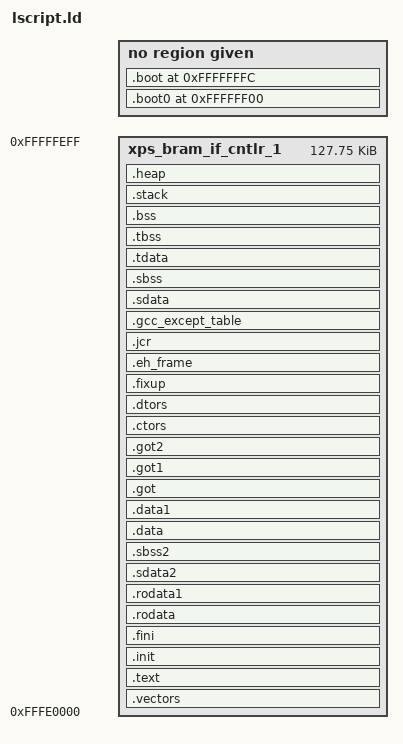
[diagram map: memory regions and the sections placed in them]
/*******************************************************************/
/*                                                                 */
/* This file is automatically generated by linker script generator.*/
/*                                                                 */
/* Version: Xilinx EDK 13.4 EDK_O.87xd                                */
/*                                                                 */
/* Copyright (c) 2010 Xilinx, Inc.  All rights reserved.           */
/*                                                                 */
/* Description : PowerPC440 Linker Script                          */
/*                                                                 */
/*******************************************************************/

_STACK_SIZE = DEFINED(_STACK_SIZE) ? _STACK_SIZE : 0x4000;
_HEAP_SIZE = DEFINED(_HEAP_SIZE) ? _HEAP_SIZE : 0x4000;
/* Define Memories in the system */

MEMORY
{
   xps_bram_if_cntlr_1 : ORIGIN = 0xFFFE0000, LENGTH = 0x0001FF00
}

/* Specify the default entry point to the program */

ENTRY(_boot)
STARTUP(boot.o)

/* Define the sections, and where they are mapped in memory */

SECTIONS
{
.vectors : {
   __vectors_start = .;
   *(.vectors)
   __vectors_end = .;
} > xps_bram_if_cntlr_1

.text : {
   *(.text)
   *(.text.*)
   *(.gnu.linkonce.t.*)
} > xps_bram_if_cntlr_1

.init : {
   KEEP (*(.init))
} > xps_bram_if_cntlr_1

.fini : {
   KEEP (*(.fini))
} > xps_bram_if_cntlr_1

.rodata : {
   __rodata_start = .;
   *(.rodata)
   *(.rodata.*)
   *(.gnu.linkonce.r.*)
   __rodata_end = .;
} > xps_bram_if_cntlr_1

.rodata1 : {
   __rodata1_start = .;
   *(.rodata1)
   *(.rodata1.*)
   __rodata1_end = .;
} > xps_bram_if_cntlr_1

.sdata2 : {
   __sdata2_start = .;
   *(.sdata2)
   *(.sdata2.*)
   *(.gnu.linkonce.s2.*)
   __sdata2_end = .;
} > xps_bram_if_cntlr_1

.sbss2 : {
   __sbss2_start = .;
   *(.sbss2)
   *(.sbss2.*)
   *(.gnu.linkonce.sb2.*)
   __sbss2_end = .;
} > xps_bram_if_cntlr_1

.data : {
   __data_start = .;
   *(.data)
   *(.data.*)
   *(.gnu.linkonce.d.*)
   __data_end = .;
} > xps_bram_if_cntlr_1

.data1 : {
   __data1_start = .;
   *(.data1)
   *(.data1.*)
   __data1_end = .;
} > xps_bram_if_cntlr_1

.got : {
   *(.got)
} > xps_bram_if_cntlr_1

.got1 : {
   *(.got1)
} > xps_bram_if_cntlr_1

.got2 : {
   *(.got2)
} > xps_bram_if_cntlr_1

.ctors : {
   __CTOR_LIST__ = .;
   ___CTORS_LIST___ = .;
   KEEP (*crtbegin.o(.ctors))
   KEEP (*(EXCLUDE_FILE(*crtend.o) .ctors))
   KEEP (*(SORT(.ctors.*)))
   KEEP (*(.ctors))
   __CTOR_END__ = .;
   ___CTORS_END___ = .;
} > xps_bram_if_cntlr_1

.dtors : {
   __DTOR_LIST__ = .;
   ___DTORS_LIST___ = .;
   KEEP (*crtbegin.o(.dtors))
   KEEP (*(EXCLUDE_FILE(*crtend.o) .dtors))
   KEEP (*(SORT(.dtors.*)))
   KEEP (*(.dtors))
   __DTOR_END__ = .;
   ___DTORS_END___ = .;
} > xps_bram_if_cntlr_1

.fixup : {
   __fixup_start = .;
   *(.fixup)
   __fixup_end = .;
} > xps_bram_if_cntlr_1

.eh_frame : {
   *(.eh_frame)
} > xps_bram_if_cntlr_1

.jcr : {
   *(.jcr)
} > xps_bram_if_cntlr_1

.gcc_except_table : {
   *(.gcc_except_table)
} > xps_bram_if_cntlr_1

.sdata : {
   __sdata_start = .;
   *(.sdata)
   *(.sdata.*)
   *(.gnu.linkonce.s.*)
   __sdata_end = .;
} > xps_bram_if_cntlr_1

.sbss : {
   . = ALIGN(4);
   __sbss_start = .;
   *(.sbss)
   *(.sbss.*)
   *(.gnu.linkonce.sb.*)
   *(.scommon)
   . = ALIGN(4);
   __sbss_end = .;
} > xps_bram_if_cntlr_1

.tdata : {
   __tdata_start = .;
   *(.tdata)
   *(.tdata.*)
   *(.gnu.linkonce.td.*)
   __tdata_end = .;
} > xps_bram_if_cntlr_1

.tbss : {
   __tbss_start = .;
   *(.tbss)
   *(.tbss.*)
   *(.gnu.linkonce.tb.*)
   __tbss_end = .;
} > xps_bram_if_cntlr_1

.bss : {
   . = ALIGN(4);
   __bss_start = .;
   *(.bss)
   *(.bss.*)
   *(.gnu.linkonce.b.*)
   *(COMMON)
   . = ALIGN(4);
   __bss_end = .;
} > xps_bram_if_cntlr_1

.boot0 0xFFFFFF00 : {
   __boot0_start = .;
   *(.boot0)
   __boot0_end = .;
} 

.boot 0xFFFFFFFC : {
   __boot_start = .;
   *(.boot)
   __boot_end = .;
} 

/* Generate Stack and Heap Sections */

.stack : {
   _stack_end = .;
   . += _STACK_SIZE;
   . = ALIGN(16);
   __stack = .;
} > xps_bram_if_cntlr_1

.heap : {
   . = ALIGN(16);
   _heap_start = .;
   . += _HEAP_SIZE;
   . = ALIGN(16);
   _heap_end = .;
   _end = .;
} > xps_bram_if_cntlr_1

}

